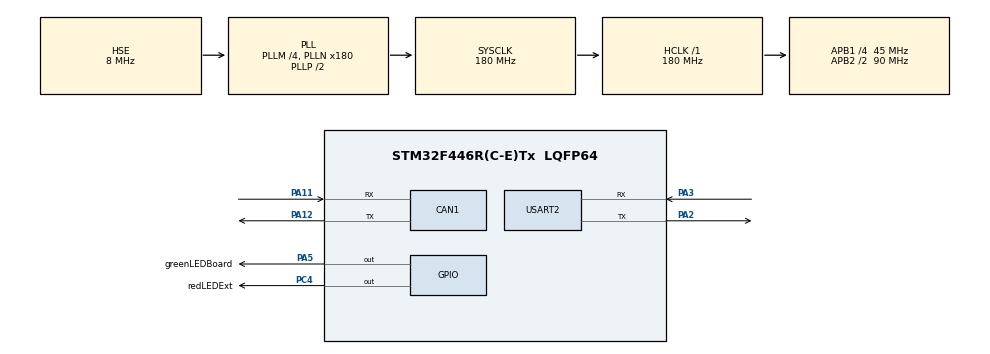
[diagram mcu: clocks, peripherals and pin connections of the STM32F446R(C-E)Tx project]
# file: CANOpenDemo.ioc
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CAN1.CalculateTimeQuantum=355.55555555555554
FREERTOS.Tasks01=defaultTask,8,256,StartDefaultTask,Default,NULL,Static,defaultTaskBuffer,defaultTaskControlBlock;ledTask,8,256,StartLEDTask,Default,NULL,Static,ledTaskBuffer,ledTaskControlBlock
FREERTOS.configMINIMAL_STACK_SIZE=256
Mcu.Family=STM32F4
Mcu.Name=STM32F446R(C-E)Tx
Mcu.Package=LQFP64
NVIC.CAN1_RX0_IRQn=true\:5\:0\:false\:false\:true\:true\:true\:true
NVIC.CAN1_RX1_IRQn=true\:5\:0\:false\:false\:true\:true\:true\:true
NVIC.CAN1_SCE_IRQn=true\:5\:0\:false\:false\:true\:true\:true\:true
NVIC.CAN1_TX_IRQn=true\:5\:0\:false\:false\:true\:true\:true\:true
NVIC.PriorityGroup=NVIC_PRIORITYGROUP_4
NVIC.TIM1_UP_TIM10_IRQn=true\:0\:0\:false\:false\:true\:false\:false\:true
NVIC.TimeBase=TIM1_UP_TIM10_IRQn
NVIC.TimeBaseIP=TIM1
PA11.Mode=Master
PA11.Signal=CAN1_RX
PA12.Mode=Master
PA12.Signal=CAN1_TX
PA2.Mode=Asynchronous
PA2.Signal=USART2_TX
PA3.Mode=Asynchronous
PA3.Signal=USART2_RX
PA5.GPIO_Label=greenLEDBoard
PA5.Signal=GPIO_Output
PC14-OSC32_IN.Mode=LSE-External-Oscillator
PC14-OSC32_IN.Signal=RCC_OSC32_IN
PC15-OSC32_OUT.Mode=LSE-External-Oscillator
PC15-OSC32_OUT.Signal=RCC_OSC32_OUT
PC4.GPIO_Label=redLEDExt
PC4.Signal=GPIO_Output
PH0-OSC_IN.Mode=HSE-External-Oscillator
PH0-OSC_IN.Signal=RCC_OSC_IN
PH1-OSC_OUT.Mode=HSE-External-Oscillator
PH1-OSC_OUT.Signal=RCC_OSC_OUT
ProjectManager.HeapSize=0x200
ProjectManager.StackSize=0x400
ProjectManager.TargetToolchain=Makefile
RCC.AHBFreq_Value=180000000
RCC.APB1CLKDivider=RCC_HCLK_DIV4
RCC.APB1Freq_Value=45000000
RCC.APB1TimFreq_Value=90000000
RCC.APB2CLKDivider=RCC_HCLK_DIV2
RCC.APB2Freq_Value=90000000
RCC.APB2TimFreq_Value=180000000
RCC.CortexFreq_Value=180000000
RCC.HCLKFreq_Value=180000000
RCC.HSE_VALUE=8000000
RCC.PLLM=4
RCC.PLLN=180
RCC.PLLSourceVirtual=RCC_PLLSOURCE_HSE
RCC.SYSCLKFreq_VALUE=180000000
RCC.SYSCLKSource=RCC_SYSCLKSOURCE_PLLCLK
RCC.USBFreq_Value=180000000
RCC.VCOOutputFreq_Value=360000000
USART2.VirtualMode=VM_ASYNC
VP_FREERTOS_VS_CMSIS_V2.Mode=CMSIS_V2
VP_SYS_VS_tim1.Mode=TIM1
board=custom

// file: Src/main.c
/* USER CODE BEGIN Header */
/**
  ******************************************************************************
  * @file           : main.c
  * @brief          : Main program body
  ******************************************************************************
  * @attention
  *
  * <h2><center>&copy; Copyright (c) 2019 STMicroelectronics.
  * All rights reserved.</center></h2>
  *
  * This software component is licensed by ST under Ultimate Liberty license
  * SLA0044, the "License"; You may not use this file except in compliance with
  * the License. You may obtain a copy of the License at:
  *                             www.st.com/SLA0044
  *
  ******************************************************************************
  */
/* USER CODE END Header */

#include "main.h"
#include "cmsis_os.h"
#include "can.h"
#include "usart.h"
#include "gpio.h"

/* USER CODE BEGIN Includes */
#include "misc.h"

/* USER CODE END Includes */

void SystemClock_Config(void);
void MX_FREERTOS_Init(void);

int main(void)
{

  /* MCU Configuration--------------------------------------------------------*/

  /* Reset of all peripherals, Initializes the Flash interface and the Systick. */
  HAL_Init();

  /* Configure the system clock */
  SystemClock_Config();

  /* Initialize all configured peripherals */
  MX_GPIO_Init();
  MX_CAN1_Init();
  MX_USART2_UART_Init();

  /* Call init function for freertos objects (in freertos.c) */
  MX_FREERTOS_Init();

  /* Start scheduler */
  osKernelStart();

  /* We should never get here as control is now taken by the scheduler */

  /* Infinite loop */
  /* USER CODE BEGIN WHILE */
  /* Serious error happened */
  while (1)
  {
    /* USER CODE END WHILE */

  }
}

void SystemClock_Config(void)
{
  RCC_OscInitTypeDef RCC_OscInitStruct = {0};
  RCC_ClkInitTypeDef RCC_ClkInitStruct = {0};

  /** Configure the main internal regulator output voltage
  */
  __HAL_RCC_PWR_CLK_ENABLE();
  __HAL_PWR_VOLTAGESCALING_CONFIG(PWR_REGULATOR_VOLTAGE_SCALE1);
  /** Initializes the CPU, AHB and APB busses clocks
  */
  RCC_OscInitStruct.OscillatorType = RCC_OSCILLATORTYPE_HSE;
  RCC_OscInitStruct.HSEState = RCC_HSE_ON;
  RCC_OscInitStruct.PLL.PLLState = RCC_PLL_ON;
  RCC_OscInitStruct.PLL.PLLSource = RCC_PLLSOURCE_HSE;
  RCC_OscInitStruct.PLL.PLLM = 4;
  RCC_OscInitStruct.PLL.PLLN = 180;
  RCC_OscInitStruct.PLL.PLLP = RCC_PLLP_DIV2;
  RCC_OscInitStruct.PLL.PLLQ = 2;
  RCC_OscInitStruct.PLL.PLLR = 2;
  if (HAL_RCC_OscConfig(&RCC_OscInitStruct) != HAL_OK)
  {
    Error_Handler();
  }
  /** Activate the Over-Drive mode
  */
  if (HAL_PWREx_EnableOverDrive() != HAL_OK)
  {
    Error_Handler();
  }
  /** Initializes the CPU, AHB and APB busses clocks
  */
  RCC_ClkInitStruct.ClockType = RCC_CLOCKTYPE_HCLK|RCC_CLOCKTYPE_SYSCLK
                              |RCC_CLOCKTYPE_PCLK1|RCC_CLOCKTYPE_PCLK2;
  RCC_ClkInitStruct.SYSCLKSource = RCC_SYSCLKSOURCE_PLLCLK;
  RCC_ClkInitStruct.AHBCLKDivider = RCC_SYSCLK_DIV1;
  RCC_ClkInitStruct.APB1CLKDivider = RCC_HCLK_DIV4;
  RCC_ClkInitStruct.APB2CLKDivider = RCC_HCLK_DIV2;

  if (HAL_RCC_ClockConfig(&RCC_ClkInitStruct, FLASH_LATENCY_5) != HAL_OK)
  {
    Error_Handler();
  }
}

void HAL_TIM_PeriodElapsedCallback(TIM_HandleTypeDef *htim)
{
  if (htim->Instance == TIM1) {
    HAL_IncTick();
  }
}

void Error_Handler(void)
{
}

/************************ (C) COPYRIGHT STMicroelectronics *****END OF FILE****/

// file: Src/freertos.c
/* USER CODE BEGIN Header */
/**
  ******************************************************************************
  * File Name          : freertos.c
  * Description        : Code for freertos applications
  ******************************************************************************
  * @attention
  *
  * <h2><center>&copy; Copyright (c) 2019 STMicroelectronics.
  * All rights reserved.</center></h2>
  *
  * This software component is licensed by ST under Ultimate Liberty license
  * SLA0044, the "License"; You may not use this file except in compliance with
  * the License. You may obtain a copy of the License at:
  *                             www.st.com/SLA0044
  *
  ******************************************************************************
  */
/* USER CODE END Header */

#include "FreeRTOS.h"
#include "task.h"
#include "main.h"
#include "cmsis_os.h"

/* USER CODE BEGIN Includes */
#include "stm32f4xx_hal.h"
/* USER CODE END Includes */

typedef StaticTask_t osStaticThreadDef_t;
osThreadId_t defaultTaskHandle;
uint32_t defaultTaskBuffer[ 256 ];
osStaticThreadDef_t defaultTaskControlBlock;
osThreadId_t ledTaskHandle;
uint32_t ledTaskBuffer[ 256 ];
osStaticThreadDef_t ledTaskControlBlock;

void StartDefaultTask(void *argument);
void StartLEDTask(void *argument);

void MX_FREERTOS_Init(void); /* (MISRA C 2004 rule 8.1) */

void MX_FREERTOS_Init(void) {
osKernelInitialize();

  /* Create the thread(s) */
  /* definition and creation of defaultTask */
  const osThreadAttr_t defaultTask_attributes = {
    .name = "defaultTask",
    .stack_mem = &defaultTaskBuffer[0],
    .stack_size = sizeof(defaultTaskBuffer),
    .cb_mem = &defaultTaskControlBlock,
    .cb_size = sizeof(defaultTaskControlBlock),
    .priority = (osPriority_t) osPriorityLow,
  };
  defaultTaskHandle = osThreadNew(StartDefaultTask, NULL, &defaultTask_attributes);

  /* definition and creation of ledTask */
  const osThreadAttr_t ledTask_attributes = {
    .name = "ledTask",
    .stack_mem = &ledTaskBuffer[0],
    .stack_size = sizeof(ledTaskBuffer),
    .cb_mem = &ledTaskControlBlock,
    .cb_size = sizeof(ledTaskControlBlock),
    .priority = (osPriority_t) osPriorityLow,
  };
  ledTaskHandle = osThreadNew(StartLEDTask, NULL, &ledTask_attributes);

}

void StartDefaultTask(void *argument)
{
  for(;;)
  {
    osDelay(1);
  }
}

void StartLEDTask(void *argument)
{
  /* USER CODE BEGIN StartLEDTask */
  /* Infinite loop */
  for(;;)
  {
    osDelay(1000);
    HAL_GPIO_WritePin(greenLEDBoard_GPIO_Port, greenLEDBoard_Pin, GPIO_PIN_RESET);
    HAL_GPIO_WritePin(redLEDExt_GPIO_Port, redLEDExt_Pin, GPIO_PIN_SET);
    osDelay(1000);
    HAL_GPIO_WritePin(greenLEDBoard_GPIO_Port, greenLEDBoard_Pin, GPIO_PIN_SET);
    HAL_GPIO_WritePin(redLEDExt_GPIO_Port, redLEDExt_Pin, GPIO_PIN_RESET);
  }
  /* USER CODE END StartLEDTask */
}

/************************ (C) COPYRIGHT STMicroelectronics *****END OF FILE****/
